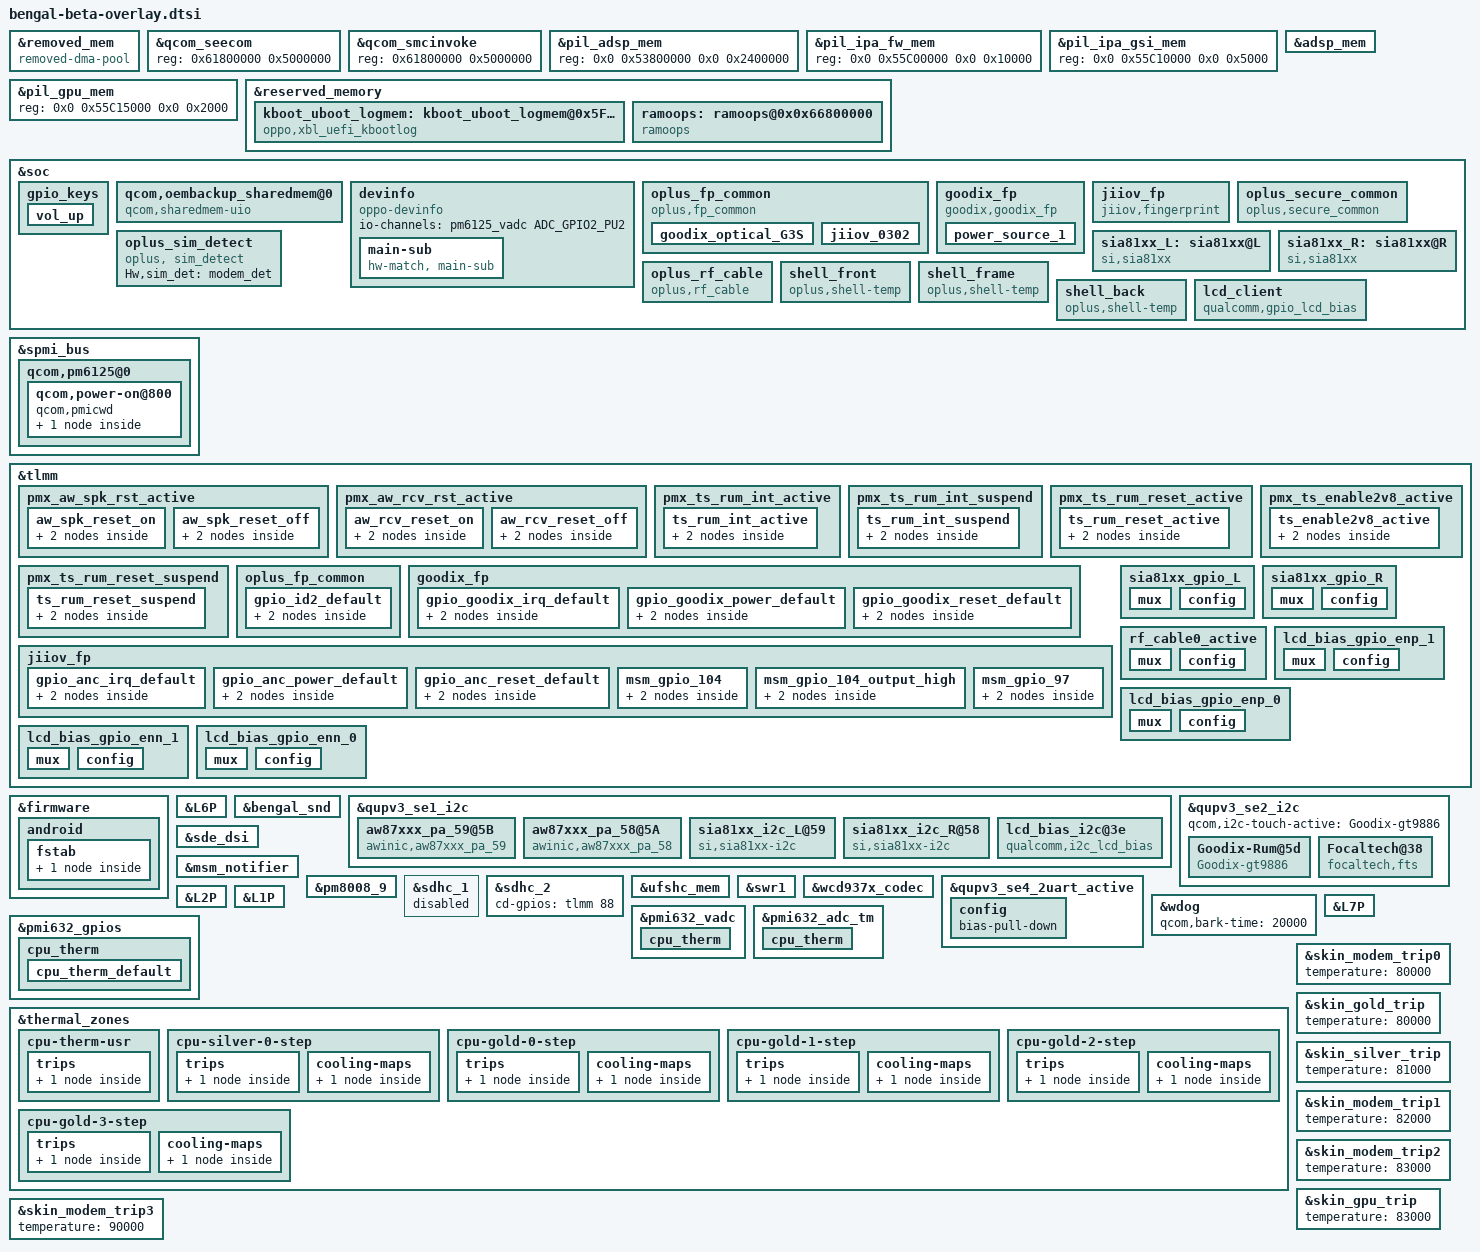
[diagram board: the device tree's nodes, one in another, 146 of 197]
/* *****************
the up part file change like:
delete note  and status = "disabled" to "ok"  add here also, other will meet can't boot issue or compile error issue
**************************/
#include "../../qcom/bengal-qrd.dtsi"
#include "dsi-panel-oplus20241-am643-samsung-fhd-video.dtsi"
#include "dsi-panel-oplus20241-s6e8fc1-samsung-fhd-video.dtsi"
#include "dsi-panel-oplus20241-s6e8fc1fe-samsung-fhd-video.dtsi"
#include "dsi-panel-ili9883a-90hz-boe-fhd-video.dtsi"

//#ifdef OPLUS_FEATURE_FINGERPRINT
&removed_mem {
	compatible = "removed-dma-pool";
	no-map;
	reg = <0x0 0x60000000 0x0 0x6800000>;
};
&qcom_seecom {
	/delete-property/ reg;
	reg = <0x61800000 0x5000000>;
};
&qcom_smcinvoke {
	/delete-property/ reg;
	reg = <0x61800000 0x5000000>;
};
//#endif /*OPLUS_FEATURE_FINGERPRINT*/

&pil_adsp_mem {
	/delete-property/ reg;
	reg = <0x0 0x53800000 0x0 0x2400000>;
};

&pil_ipa_fw_mem {
	/delete-property/ reg;
	reg = <0x0 0x55C00000 0x0 0x10000>;
};

&pil_ipa_gsi_mem {
	/delete-property/ reg;
	reg = <0x0 0x55C10000 0x0 0x5000>;
};

&pil_gpu_mem {
	/delete-property/ reg;
	reg = <0x0 0x55C15000 0x0 0x2000>;
};

&adsp_mem {
	/delete-property/ reusable;
};

// xbl_uefi_mem address get from boot_images Core.dsc.inc file: PcdEmbeddedFdBaseAddress + SERIAL_BUFFER_OFFSET,0x5FC00000+0x3F7000
// kernel boot log: 0x5FC00000~ 0x5FFF7000
&reserved_memory {
	kboot_uboot_logmem: kboot_uboot_logmem@0x5FC00000 {
		reg = <0x0 0x5FC00000 0x0 0x3FF000>;
		compatible = "oppo,xbl_uefi_kbootlog";
		xbluefi-offset = <0x3F7000>;
		no-map;
	};

	ramoops: ramoops@0x0x66800000 {
		compatible = "ramoops";
		reg = <0 0x66800000 0 0x00400000>;
		record-size =  <0x40000>; //256x1024
		console-size = <0x40000>;
		ftrace-size =  <0x40000>;
		pmsg-size=         <0x200000>;
		devinfo-size=  <0x01000>;
		ecc-size=          <0x0>;
	};
};
//bengal-qrd.dtsi
&soc {
	gpio_keys {
		vol_up {
			/delete-property/ label;
			label = "volume_down";
			/delete-property/ linux,code;
			linux,code = <KEY_VOLUMEDOWN>;
		};
	};

	//#ifdef VENDOR_EDIT
	//#ifdef FEATURE_OPPO_NV_BACKUP
	//add for creating a shared memory with uio for nv backup and restore
	qcom,oembackup_sharedmem@0 {
		compatible = "qcom,sharedmem-uio";
		reg = <0x0 0x00100000>;
		reg-names = "oembackup";
		qcom,client-id = <0x00000004>;
		qcom,guard-memory;
		qcom,vm-nav-path;
	};
	//#endif /* FEATURE_OPPO_NV_BACKUP */
	//#endif /* VENDOR_EDIT */

	devinfo {
		compatible = "oppo-devinfo";

		io-channels= <&pm6125_vadc ADC_GPIO2_PU2>;
		io-channel-names= "vph_pwr_voltage_sub";

		main-sub {
			compatible = "hw-match, main-sub";
			use_pmic_adc;
			adc_ranges = <0 80
					80 180
					180 300
					300 420
					420 550
					550 650
					650 760
					760 850
					850 950>;
			aboard-patterns = <0 1 1 1 0 1 0>;

			/*main board*/
			match-projects = <20241 20242 20243 20245 20246 20247 21233>;
		};
	};

	//#ifdef OPLUS_FEATURE_FINGERPRINT
	oplus_fp_common {
		compatible = "oplus,fp_common";
		oplus,fp_gpio_num = <1>;
		oplus,fp_gpio_0 = <&tlmm 67 0x0>;
		pinctrl-names = "default";
		pinctrl-0 = <&gpio_id2_default>;
		goodix_optical_G3S {
			oplus,fp-id = <1>; /* fp id mapping table */
			vendor-chip = <11>; /* please refer to the struct fp_vendor_t in oppo_fp_commmon.n */
			eng-menu = "-1,-1"; /* represents SNR, inclination test item in engineer menu, and 0/1 means off/on */
			chip-name = "G_OPTICAL_G3S";  /* /proc/fp_id, will be displayed in engineer menu  */
		};
        jiiov_0302 {
            oplus,fp-id = <0>; /* fp id mapping table */
            vendor-chip = <23>; /* please refer to the struct fp_vendor_t in oppo_fp_commmon.n */
            eng-menu = "-1,-1"; /* represents SNR, inclination test item in engineer menu, and 0/1 means off/on */
            chip-name = "JIIOV_0302";  /* /proc/fp_id, will be displayed in engineer menu  */
        };
	};
	goodix_fp {
		status = "ok";
		compatible = "goodix,goodix_fp";
		interrupt-parent = <&tlmm>;
		interrupts = <97 0>;
		goodix,gpio_irq = <&tlmm 97 0x1>;
		gpio-power = <&tlmm 101 0x0>;
		goodix,gpio_reset = <&tlmm 104 0x0>;
		pinctrl-names = "default";
		pinctrl-0 = <&gpio_goodix_irq_default>, <&gpio_goodix_power_default>, <&gpio_goodix_reset_default>;
		notify_tpinfo_flag = <1>;
		power-num = <1>;
		power_source_1 {
			power-mode = <2>;
			power-name = "gpio-power";
			delay-time = <0>;
		};
	};
    jiiov_fp {
        status = "ok";
        compatible = "jiiov,fingerprint";
        interrupt-parent = <&tlmm>;
        interrupts = <97 0x0>;
        anc,gpio_irq = <&tlmm 97 0x1>;
        anc,gpio_rst = <&tlmm 104 0x0>;
        anc,gpio_pwr = <&tlmm 101 0x0>;
        anc,enable-via-gpio;
        /* anc,enable-wakeup; */
        pinctrl-names = "default", "anc_reset_reset", "anc_reset_active", "anc_irq_active";
        pinctrl-0 = <&gpio_anc_irq_default>, <&gpio_anc_power_default>, <&gpio_anc_reset_default>;
        pinctrl-1 = <&msm_gpio_104>;
        pinctrl-2 = <&msm_gpio_104_output_high>;
        pinctrl-3 = <&msm_gpio_97>;
    };
	//#endif /*OPLUS_FEATURE_FINGERPRINT*/
    // #ifdef OPLUS_FEATURE_SECURITY_COMMON
    oplus_secure_common {
        compatible = "oplus,secure_common";
    };
    //#endif /* OPLUS_FEATURE_SECURITY_COMMON */

	//#ifdef OPLUS_FEATRUE_SIM_HOLDER_DETECT
	oplus_sim_detect {
		compatible = "oplus, sim_detect";
		Hw,sim_det = "modem_det";
	};
	//#endif /* OPLUS_FEATRUE_SIM_HOLDER_DETECT */

	//#ifdef OPLUS_ARCH_EXTENDS
	sia81xx_L: sia81xx@L {
			compatible = "si,sia81xx";
			si,sia81xx_type = "sia8152";
			si,sia81xx_reset = <&tlmm 98 0x00>;
			si,sia81xx_owi = <&tlmm 98 0x00>;
			pinctrl-names = "sia81xx_gpio";
			pinctrl-0 = <&sia81xx_gpio_L>;

			si,sia81xx_disable_pin = <1>;

			/* the same value share a same task
			 * valid value range : 0 ~ 7 */
			timer_task_hdl = <0>;

			channel_num = <0>;
			owi_mode = <6>;
			en_x_filter = <1>;
			en_dynamic_updata_vdd = <1>;
			dynamic_updata_vdd_port = <0xb030>;
	};

	sia81xx_R: sia81xx@R {
			compatible = "si,sia81xx";
			si,sia81xx_type = "sia8152";
			si,sia81xx_reset = <&tlmm 107 0x00>;
			si,sia81xx_owi = <&tlmm 107 0x00>;
			pinctrl-names = "sia81xx_gpio";
			pinctrl-0 = <&sia81xx_gpio_R>;

			si,sia81xx_disable_pin = <1>;

			/* the same value share a same task
			 * valid value range : 0 ~ 7 */
			timer_task_hdl = <0>;

			channel_num = <1>;
			owi_mode = <6>;
			en_x_filter = <0>;
			en_dynamic_updata_vdd = <1>;
			dynamic_updata_vdd_port = <0xb030>;
	};
	//#endif /* OPLUS_ARCH_EXTENDS */

	//#ifdef VENDOR_EDIT
	oplus_rf_cable {
		compatible = "oplus,rf_cable";
		interrupt-parent = <&tlmm>;
		rf_cable_support_num = <1>;
		rf,cable0-gpio = <&tlmm 106 0>;
		rf,cable-support-timer = <0>;
		pinctrl-names = "rf_cable_active";
		pinctrl-0 = <&rf_cable0_active>;
	};
	//#endif /* VENDOR_EDIT */

	//#ifdef OPLUS_FEATURE_THERMAL_HORAE
	shell_front {
		compatible = "oplus,shell-temp";
	};

	shell_frame {
		compatible = "oplus,shell-temp";
	};

	shell_back {
		compatible = "oplus,shell-temp";
	};
	//#endif /* OPLUS_FEATURE_THERMAL_HORAE */
	lcd_client {
		compatible = "qualcomm,gpio_lcd_bias";
		pinctrl-names = "lcd_bias_gpio_enp0","lcd_bias_gpio_enp1","lcd_bias_gpio_enn0","lcd_bias_gpio_enn1";
		pinctrl-0 = <&lcd_bias_gpio_enp_0>;
		pinctrl-1 = <&lcd_bias_gpio_enp_1>;
		pinctrl-2 = <&lcd_bias_gpio_enn_0>;
		pinctrl-3 = <&lcd_bias_gpio_enn_1>;
		status = "okay";
	};
};
&spmi_bus {
	qcom,pm6125@0 {
		qcom,power-on@800 {
			qcom,pmicwd;
			qcom,pon_2 {
				qcom,pon-type = <1>;
				qcom,pull-up = <1>;
				linux,code = <KEY_VOLUMEUP>;
			};
		};
    };
};

&tlmm {
	pmx_aw_spk_rst_active {
		aw_spk_reset_on: aw_spk_reset_on {
			mux {
				pins = "gpio84";
				function = "gpio";
			};

			config {
				pins = "gpio84";
				drive-strength = <8>;
				bias-pull-up;
			};
		};

		aw_spk_reset_off: aw_spk_reset_off {
			mux {
				pins = "gpio84";
				function = "gpio";
			};

			config {
				pins = "gpio84";
				drive-strength = <2>;
				bias-pull-down;
			};
		};
	};

	pmx_aw_rcv_rst_active {
		aw_rcv_reset_on: aw_rcv_reset_on {
			mux {
				pins = "gpio111";
				function = "gpio";
			};

			config {
				pins = "gpio111";
				drive-strength = <8>;
				bias-pull-up;
			};
		};

		aw_rcv_reset_off: aw_rcv_reset_off {
			mux {
				pins = "gpio111";
				function = "gpio";
			};

			config {
				pins = "gpio111";
				drive-strength = <2>;
				bias-pull-down;
			};
		};
	};


	pmx_ts_rum_int_active {
		ts_rum_int_active: ts_rum_int_active {
			mux {
				pins = "gpio80";
				function = "gpio";
			};

			config {
				pins = "gpio80";
				drive-strength = <8>;
				bias-disable;
			};
		};
	};

	pmx_ts_rum_int_suspend {
		ts_rum_int_suspend: ts_rum_int_suspend {
			mux {
				pins = "gpio80";
				function = "gpio";
			};

			config {
				pins = "gpio80";
				drive-strength = <2>;
				bias-pull-down;
			};
		};
	};

	pmx_ts_rum_reset_active {
		ts_rum_reset_active: ts_rum_reset_active {
			mux {
				pins = "gpio71";
				function = "gpio";
			};

			config {
				pins = "gpio71";
				drive-strength = <8>;
				output-low;
				bias-disable;
			};
		};
	};

	pmx_ts_rum_reset_suspend {
		ts_rum_reset_suspend: ts_rum_reset_suspend {
			mux {
				pins = "gpio71";
				function = "gpio";
			};

			config {
				pins = "gpio71";
				drive-strength = <2>;
				bias-pull-down;
			};
		};
	};

	pmx_ts_enable2v8_active {
		ts_enable2v8_active: ts_enable2v8_active {
			mux {
				pins = "gpio85";
				function = "gpio";
			};

			config {
				pins = "gpio85";
				drive-strength = <8>;
				bias-pull-up;
			};
		};
	};

	//#ifdef OPLUS_FEATURE_FINGERPRINT
	oplus_fp_common{
		gpio_id2_default: gpio_id2_default {
			mux {
				pins = "gpio67";
				function = "gpio";
			};
			config {
				pins = "gpio67";
				drive-strength = <2>;
				bias-pull-up;
				input-enable;
			};
		};
	};

	goodix_fp{
		gpio_goodix_irq_default: gpio_goodix_irq_default {
			mux {
				pins = "gpio97";
				function = "gpio";
			};
			config {
				pins = "gpio97";
				drive-strength = <2>;
				bias-pull-down;
				input-enable;
			};
		};
		gpio_goodix_power_default: gpio_goodix_power_default {
			mux {
				pins = "gpio101";
				function = "gpio";
			};
			config {
				pins = "gpio101";
				drive-strength = <2>;
				bias-disable;
				output-low;
			};
		};
		gpio_goodix_reset_default: gpio_goodix_reset_default {
			mux {
				pins = "gpio104";
				function = "gpio";
			};
			config {
				pins = "gpio104";
				drive-strength = <2>;
				bias-disable;
				output-low;
			};
		};
	};

    jiiov_fp{
        gpio_anc_irq_default: gpio_anc_irq_default {
            mux {
                pins = "gpio97";
                function = "gpio";
            };
            config {
                pins = "gpio97";
                drive-strength = <2>;
                bias-pull-down;
                input-enable;
            };
        };
        gpio_anc_power_default: gpio_anc_power_default {
            mux {
                pins = "gpio101";
                function = "gpio";
            };
            config {
                pins = "gpio101";
                drive-strength = <2>;
                bias-disable;
                output-low;
            };
        };
        gpio_anc_reset_default: gpio_anc_reset_default {
            mux {
                pins = "gpio104";
                function = "gpio";
            };
            config {
                pins = "gpio104";
                drive-strength = <2>;
                bias-disable;
                output-low;
            };
        };

        msm_gpio_104: msm_gpio_104 {
            mux {
                pins = "gpio104";
                function = "gpio";
            };

            config {
                pins = "gpio104";
                drive-strength = <2>;
                bias-disable;
                output-low;
            };
        };

        // GPIO_104 : FP_RESET_N, state device active
        msm_gpio_104_output_high: msm_gpio_104_output_high {
            mux {
                pins = "gpio104";
                function = "gpio";
            };

            config {
                pins = "gpio104";
                drive-strength = <2>;
                bias-disable;
                output-high;
            };
        };

        // GPIO_97 : FP_INT_N
        msm_gpio_97: msm_gpio_97 {
            mux {
                pins = "gpio97";
                function = "gpio";
            };

            config {
                pins = "gpio97";
                drive-strength = <2>;
                bias-pull-down;
            };
        };
    };
	//#endif /*OPLUS_FEATURE_FINGERPRINT*/

	//#ifdef OPLUS_ARCH_EXTENDS
	sia81xx_gpio_L: sia81xx_gpio_L {
		mux {
			pins = "gpio98", "gpio98";
			function = "gpio";
		};

		config {
			pins = "gpio98", "gpio98";
			drive-strength = <6>;
			bias-disable;
		};
	};

	sia81xx_gpio_R: sia81xx_gpio_R {
		mux {
			pins = "gpio107", "gpio107";
			function = "gpio";
		};

		config {
			pins = "gpio107", "gpio107";
			drive-strength = <6>;
			bias-disable;
		};
	};
	//#endif /* OPLUS_ARCH_EXTENDS */

	//#ifdef VENDOR_EDIT
	rf_cable0_active: rf_cable0_active {
		mux {
			pins = "gpio106";
			function = "gpio";
		};
		config {
			pins = "gpio106";
			drive-strength = <2>;
			input-enable;
			bias-pull-up;
		};
	};
	//#endif /* VENDOR_EDIT */
	lcd_bias_gpio_enp_1: lcd_bias_gpio_enp_1 {
		mux {
			pins = "gpio52";
			function = "gpio";
		};

		config {
			pins = "gpio52";
			drive-strength = <8>;
			output-high;
			bias-pull-up;
		};
	};

	lcd_bias_gpio_enp_0: lcd_bias_gpio_enp_0 {
		mux {
			pins = "gpio52";
			function = "gpio";
		};

		config {
			pins = "gpio52";
			drive-strength = <2>;
			output-low;
			bias-pull-down;
		};
	};

	lcd_bias_gpio_enn_1: lcd_bias_gpio_enn_1 {
		mux {
			pins = "gpio54";
			function = "gpio";
		};

		config {
			pins = "gpio54";
			drive-strength = <8>;
			output-high;
			bias-pull-up;
		};
	};

	lcd_bias_gpio_enn_0: lcd_bias_gpio_enn_0 {
		mux {
			pins = "gpio54";
			function = "gpio";
		};

		config {
			pins = "gpio54";
			drive-strength = <2>;
			output-low;
			bias-pull-down;
		};
	};
};

&firmware {
	android {
		fstab {
			vendor {
				/delete-property/ fsmgr_flags;
				fsmgr_flags = "wait,avb";
			};
		};
	};
};

&L6P {
	/delete-property/ regulator-min-microvolt;
	/delete-property/ regulator-max-microvolt;
	regulator-min-microvolt = <2800000>;
	regulator-max-microvolt = <3400000>;
};

&bengal_snd {
	/delete-property/ qcom,wsa-max-devs;
	/delete-property/ qcom,wsa-devs;
	qcom,wsa-max-devs = <0>;
	qcom,wsa-devs = <0>;

	qcom,msm-mbhc-hs-mic-max-threshold-mv = <2600>;
	qcom,msm-mbhc-hs-mic-min-threshold-mv = <75>;

	si,sia81xx-max-num = <2>;
	si,sia81xx-aux-devs = <&sia81xx_L>, <&sia81xx_R>;
	si,sia81xx-aux-devs-prefix = "SpkrMonoL", "SpkrMonoR";

	oplus,mbhc-headset-micbias-alwayon = <1>;
};

&qupv3_se1_i2c {
	/delete-node/ nq;

	aw87xxx_pa_59@5B{
		compatible = "awinic,aw87xxx_pa_59";
		reg = <0x5B>;
		oplus-real-addr = <0x59>;

		pa-channel = < 0 >;
		/* actflag-gain-array: off music voice fm rcv */
		actflag-gain-array = < 0x00 0x08 0x08 0x08 0x00 >;
		/*actflag-auto-run;*/
		gain-reg-addr = <0x06>;
		monitor-flag = <1>;
		monitor-timer-val = <3000>;
		monitor-timer-count-max = <5>;

		reset-gpio = <&tlmm 84 0x00>;
		pinctrl-names = "spk_reset_on", "spk_reset_off";
		pinctrl-0 = <&aw_spk_reset_on>;
		pinctrl-1 = <&aw_spk_reset_off>;

		status = "okay";
	};

	aw87xxx_pa_58@5A{
		compatible = "awinic,aw87xxx_pa_58";
		reg = <0x5A>;
		oplus-real-addr = <0x58>;
		// AW87339
		reset-gpio = <&tlmm 111 0x00>;
		pinctrl-names = "rcv_reset_on", "rcv_reset_off";
		pinctrl-0 = <&aw_rcv_reset_on>;
		pinctrl-1 = <&aw_rcv_reset_off>;

		// AW87359
		pa-channel = < 1 >;
		/* actflag-gain-array: off music voice fm rcv */
		actflag-gain-array = < 0x00 0x08 0x08 0x08 0x00 >;
		/*actflag-auto-run;*/
		gain-reg-addr = <0x06>;
		monitor-flag = <1>;
		monitor-timer-val = <3000>;
		monitor-timer-count-max = <5>;

		status = "okay";
	};

	sia81xx_i2c_L@59 {
		compatible = "si,sia81xx-i2c";
		reg = <0x59>;

		si,sia81xx-dev = <&sia81xx_L>;
	};

	sia81xx_i2c_R@58 {
		compatible = "si,sia81xx-i2c";
		reg = <0x58>;
		si,sia81xx-dev = <&sia81xx_R>;
	};

    lcd_bias_i2c@3e {
		compatible = "qualcomm,i2c_lcd_bias";
		reg = <0x3e>;
		qualcomm,enp = <&tlmm 52 0x0>;
		qualcomm,enn = <&tlmm 54 0x0>;
		status = "okay";
	};

};
&qupv3_se2_i2c {
	/delete-property/ qcom,i2c-touch-active;
	qcom,i2c-touch-active="Goodix-gt9886";
	/delete-node/ synaptics_tcm;

	Goodix-Rum@5d {
		compatible = "Goodix-gt9886";
		reg = <0x5d>;
		chip-name = "GT9886";

		/* Interrupt && Irq-gpio */
		interrupt-parent = <&tlmm>;
		interrupts = <80 0x2002>;

		/* Power Config */
		//vdd_2v8-supply = <&L6P>;
		vcc_1v8-supply = <&L9A>;
		//vdd_2v8_volt = <3000000>;

		/* Other HW Resource */
		irq-gpio = <&tlmm 80 0x2002>;
		reset-gpio = <&tlmm 71 0x1>;
		enable2v8_gpio = <&tlmm 85 0x1>;
		pinctrl-names = "default";
		pinctrl-0 = <&ts_enable2v8_active &ts_rum_reset_active &ts_rum_int_active>;

		vid_len = <2>;
		tp_type = <8>;
		// type of tp_dev ,TP-SAMSUNG = 8;
		platform_support_project = <20241 20242 20243 20245 20246 20247 21233 20241 20242 20243 20245 20246 20247 21233>;
		platform_support_project_dir = <20241 20241 20241 20241 20241 20241 20241 20241 20241 20241 20241 20241 20241 20241>;
		platform_support_project_commandline = "mdss_s6e8fc1_samsung_video", "mdss_s6e8fc1_samsung_video", "mdss_s6e8fc1_samsung_video",
                        "mdss_s6e8fc1_samsung_video", "mdss_s6e8fc1_samsung_video", "mdss_s6e8fc1_samsung_video", "mdss_s6e8fc1_samsung_video",
                        "mdss_s6e8fc1fe_samsung_video", "mdss_s6e8fc1fe_samsung_video", "mdss_s6e8fc1fe_samsung_video",
                        "mdss_s6e8fc1fe_samsung_video", "mdss_s6e8fc1fe_samsung_video", "mdss_s6e8fc1fe_samsung_video", "mdss_s6e8fc1fe_samsung_video";
		platform_support_project_external_name = "AAA01", "AAA01", "AAA01", "AAA01", "AAA01", "AAA01", "AAA48",
                        "AA001", "AA001", "AA001", "AA001", "AA001", "AA001", "AA248";

		touchpanel,max-num-support = <10>;
		touchpanel,tx-rx-num = <16 34>;
		touchpanel,panel-coords = <5400 12000>;
		touchpanel,display-coords = <1080 2400>;
		touchpanel,touchmajor-limit = <0 270>;

		/* SW Support Feature Control */
		register-is-16bit;
		black_gesture_support;
		fw_edge_limit_support;
		pressure_report_support;
		charger_pump_support;
		game_switch_support;
		smart_gesture_support;
		fw_update_app_support;
		fingerprint_underscreen_support;
		esd_handle_support;
		new_set_irq_wake_support;
		health_monitor_v2_support;
		irq_need_dev_resume_ok;

		touchpanel,button-type = <4>;
		touchpanel.button-TRx = <0 0>;
	};

	Focaltech@38 {
		compatible = "focaltech,fts";
		reg = <0x38>;
		chip-name = "FT3518";

		/* Interrupt && Irq-gpio */
		interrupt-parent = <&tlmm>;
		interrupts = <80 0x2002>;

		/* Power Config */
		enable2v8_gpio = <&tlmm 85 0x1>;
		//vdd_2v8-supply = <&L6P>;
		vcc_1v8-supply = <&L9A>;
		//vdd_2v8_volt = <3000000>;

		/* Other HW Resource */
		irq-gpio = <&tlmm 80 0x2002>;
		reset-gpio = <&tlmm 71 0x1>;
		pinctrl-names = "default";
		pinctrl-0 = <&ts_enable2v8_active &ts_rum_reset_active &ts_rum_int_active>;

		vid_len = <2>;
		tp_type = <8>;
		// type of tp_dev ,TP-SAMSUNG = 8;
		platform_support_project = <20241 20242 20243 20245 20246 20247>;
		platform_support_project_dir = <20241 20241 20241 20241 20241 20241>;
		platform_support_project_commandline = "mdss_am643_samsung_video", "mdss_am643_samsung_video", "mdss_am643_samsung_video",
                        "mdss_am643_samsung_video", "mdss_am643_samsung_video", "mdss_am643_samsung_video";
		platform_support_project_external_name = "AA001", "AA001", "AA001", "AA001", "AA001", "AA001";

		touchpanel,max-num-support = <10>;
		touchpanel,tx-rx-num = <15 34>;
		touchpanel,panel-coords = <1080 2400>;
		touchpanel,display-coords = <1080 2400>;
		touchpanel,touchmajor-limit = <0 54>;

		/* SW Support Feature Control */
		black_gesture_support;
		fw_edge_limit_support;
		pressure_report_support;
		charger_pump_support;
		game_switch_support;
		smart_gesture_support;
		fw_update_app_support;
		fingerprint_underscreen_support;
		esd_handle_support;
		new_set_irq_wake_support;
		health_monitor_v2_support;
		irq_need_dev_resume_ok;

		touchpanel,button-type = <4>;
		touchpanel.button-TRx = <0 0>;
	};
};

&sde_dsi {
	/delete-property/ pinctrl-0;
	/delete-property/ pinctrl-1;
	pinctrl-0 = <&sde_dsi_active &sde_te_active>;
	pinctrl-1 = <&sde_dsi_suspend &sde_te_suspend>;
	/delete-property/ qcom,dsi-default-panel;
	qcom,dsi-default-panel = <&dsi_ili9883a_90hz_boe_video>;
};
&msm_notifier {
	/delete-property/ panel;
	panel = <&dsi_s6e8fc1_samsung_video
		&dsi_s6e8fc1_samsung_video>;
};

&pm8008_9{
	status = "okay";
};

/* #ifdef OPLUS_FEATURE_EMMC_DRIVER */
&sdhc_1 {
       status = "disabled";
};

&sdhc_2 {
       cd-gpios = <&tlmm 88 GPIO_ACTIVE_HIGH>;
       status = "ok";
};
/* #endif */

/* config spm-level from 5 to 3 */
&ufshc_mem {
        spm-level = <3>;
        vccq2-voltage-level = <1800000 1800000>;
};

//bengal-audio-overlay.dtsi
&swr1 {
	/delete-property/ qcom,disable-div2-clk-switch;
};
&wcd937x_codec {
	/delete-property/ qcom,cdc-micbias1-mv;
	/delete-property/ qcom,cdc-micbias2-mv;
	/delete-property/ qcom,cdc-micbias3-mv;
	qcom,cdc-micbias1-mv = <2700>;
	qcom,cdc-micbias2-mv = <2700>;
	qcom,cdc-micbias3-mv = <2700>;
};

/*BSP.Kernel.Debug, 2019/06/22, Modify for avoid noise, change from no-pull to bias-pull-down*/
&qupv3_se4_2uart_active {
	config {
	/delete-property/ bias-disable;
	bias-pull-down;
	};
};

&L6P {
	regulator-min-microvolt = <1800000>;
	regulator-max-microvolt = <1800000>;
};
&L2P {
	regulator-min-microvolt = <1050000>;
	regulator-max-microvolt = <1050000>;
};
&L1P {
	regulator-min-microvolt = <1150000>;
	regulator-max-microvolt = <1150000>;
};

//modify bark time to 20s
&wdog {
	/delete-property/ qcom,bark-time;
	qcom,bark-time = <20000>;
};

&L7P {
	regulator-min-microvolt = <3300000>;
	regulator-max-microvolt = <3300000>;
	regulator-always-on;
};

//#ifdef OPLUS_FEATURE_THERMAL_HORAE
/* add for thermal */
&pmi632_vadc {
	pinctrl-0 = <&conn_therm_default &skin_therm_default &cpu_therm_default>;

	cpu_therm {
		reg = <ADC_AMUX_THM1_PU2>;
		label = "cpu_therm";
		qcom,ratiometric;
		qcom,hw-settle-time = <200>;
		qcom,pre-scaling = <1 1>;
	};
};

&pmi632_gpios {
	cpu_therm {
		cpu_therm_default: cpu_therm_default {
		   pins = "gpio5";
		   bias-high-impedance;
	   };
	};
};

&pmi632_adc_tm {
	io-channels = <&pmi632_vadc ADC_GPIO2_PU2>,
			<&pmi632_vadc ADC_AMUX_THM1_PU2>;

	cpu_therm {
		reg = <ADC_AMUX_THM1_PU2>;
		qcom,ratiometric;
		qcom,hw-settle-time = <200>;
	};
};

&thermal_zones {
	cpu-therm-usr {
		polling-delay-passive = <0>;
		polling-delay = <0>;
		thermal-governor = "user_space";
		thermal-sensors = <&pmi632_adc_tm ADC_AMUX_THM1_PU2>;
		wake-capable-sensor;
		trips {
			active-config0 {
				temperature = <125000>;
				hysteresis = <1000>;
				type = "passive";
			};
		};
	};

	cpu-silver-0-step {
		polling-delay-passive = <0>;
		polling-delay = <0>;
		thermal-governor = "step_wise";
		thermal-sensors = <&tsens0 12>;
		wake-capable-sensor;

		trips {
			cs0_config: cs0-config {
				temperature = <85000>;
				hysteresis = <2000>;
				type = "passive";
			};
		};

		cooling-maps {
			cs0_cdev {
				trip = <&cs0_config>;
				cooling-device = <&CPU0 THERMAL_NO_LIMIT
							THERMAL_NO_LIMIT>;
			};
		};
	};

	cpu-gold-0-step {
		polling-delay-passive = <0>;
		polling-delay = <0>;
		thermal-governor = "step_wise";
		thermal-sensors = <&tsens0 6>;
		wake-capable-sensor;

		trips {
			cg0_config: cg0-config {
				temperature = <85000>;
				hysteresis = <2000>;
				type = "passive";
			};
		};

		cooling-maps {
			cg0_cdev {
				trip = <&cg0_config>;
				cooling-device = <&CPU4 THERMAL_NO_LIMIT 1>;
			};
		};
	};

	cpu-gold-1-step {
		polling-delay-passive = <0>;
		polling-delay = <0>;
		thermal-governor = "step_wise";
		thermal-sensors = <&tsens0 7>;
		wake-capable-sensor;

		trips {
			cg1_config: cg1-config {
				temperature = <85000>;
				hysteresis = <2000>;
				type = "passive";
			};
		};

		cooling-maps {
			cg1_cdev {
				trip = <&cg1_config>;
				cooling-device = <&CPU4 THERMAL_NO_LIMIT 1>;
			};
		};
	};

	cpu-gold-2-step {
		polling-delay-passive = <0>;
		polling-delay = <0>;
		thermal-governor = "step_wise";
		thermal-sensors = <&tsens0 8>;
		wake-capable-sensor;

		trips {
			cg2_config: cg2-config {
				temperature = <85000>;
				hysteresis = <2000>;
				type = "passive";
			};
		};

		cooling-maps {
			cg2_cdev {
				trip = <&cg2_config>;
				cooling-device = <&CPU4 THERMAL_NO_LIMIT 1>;
			};
		};
	};

	cpu-gold-3-step {
		polling-delay-passive = <0>;
		polling-delay = <0>;
		thermal-governor = "step_wise";
		thermal-sensors = <&tsens0 9>;
		wake-capable-sensor;

		trips {
			cg3_config: cg3-config {
				temperature = <85000>;
				hysteresis = <2000>;
				type = "passive";
			};
		};

		cooling-maps {
			cg3_cdev {
				trip = <&cg3_config>;
				cooling-device = <&CPU4 THERMAL_NO_LIMIT 1>;
			};
		};
	};
};

/* delete low battery policy for performance 
&thermal_soc_cooling_maps {
	/delete-node/ soc_cpu0;
	/delete-node/ soc_cpu4;
	/delete-node/ soc_cpu6;
	/delete-node/ soc_cpu7;
};*/

/* increase the trigger temp */
&skin_modem_trip0 {
	temperature = <80000>;
};

&skin_gold_trip {
	temperature = <80000>;
};

&skin_silver_trip {
	temperature = <81000>;
};

&skin_modem_trip1 {
	temperature = <82000>;
};

&skin_modem_trip2 {
	temperature = <83000>;
};

&skin_gpu_trip {
	temperature = <83000>;
};

&skin_modem_trip3 {
	temperature = <90000>;
};
//#endif /* OPLUS_FEATURE_THERMAL_HORAE */
